AUTOSAR XML (schema 4-2-2)
package /Components
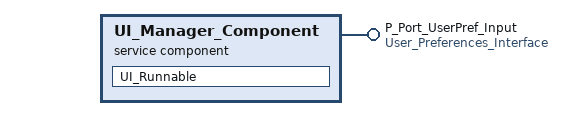
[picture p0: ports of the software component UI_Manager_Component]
  service sw component type UI_Manager_Component
    provide port P_Port_UserPref_Input: provided-interface=User_Preferences_Interface
    behavior UI_Manager_Behavior: handle-termination-and-restart=true
      init event Init_E: start-on-event=UI_Runnable
      runnable UI_Runnable: minimum-start-interval=100, symbol=UI_PREF_Send_Symbol
        data-read-access:
          access ENV_Read: accessed-variable=ENVIRONMENT_DATA
        data-send-points:
          access UI_Pref_Send: accessed-variable=ENVIRONMENT_DATA
